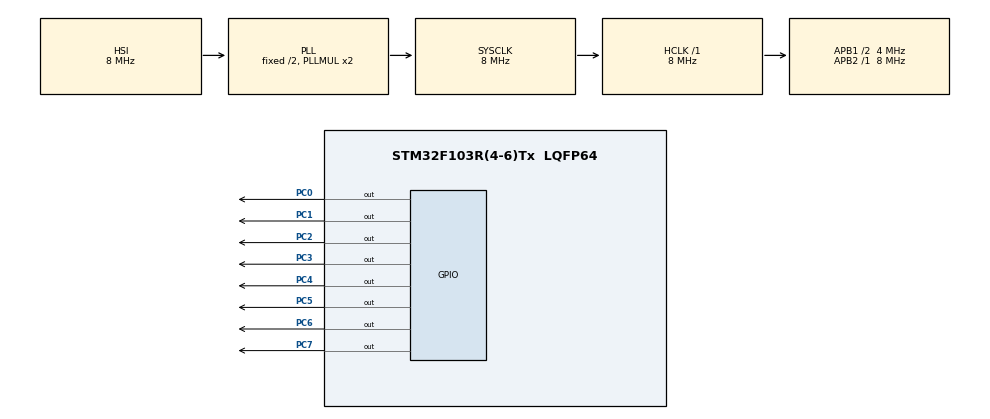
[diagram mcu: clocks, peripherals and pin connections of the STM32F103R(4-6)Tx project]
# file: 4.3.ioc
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Mcu.Family=STM32F1
Mcu.Name=STM32F103R(4-6)Tx
Mcu.Package=LQFP64
NVIC.PriorityGroup=NVIC_PRIORITYGROUP_4
NVIC.TIM3_IRQn=true\:0\:0\:false\:false\:true\:true\:true
PC0.Signal=GPIO_Output
PC1.Signal=GPIO_Output
PC2.Signal=GPIO_Output
PC3.Signal=GPIO_Output
PC4.Signal=GPIO_Output
PC5.Signal=GPIO_Output
PC6.Signal=GPIO_Output
PC7.Signal=GPIO_Output
ProjectManager.HeapSize=0x200
ProjectManager.StackSize=0x400
ProjectManager.TargetToolchain=STM32CubeIDE
RCC.AHBFreq_Value=8000000
RCC.APB1CLKDivider=RCC_HCLK_DIV2
RCC.APB1Freq_Value=4000000
RCC.APB1TimFreq_Value=8000000
RCC.APB2Freq_Value=8000000
RCC.APB2TimFreq_Value=8000000
RCC.HCLKFreq_Value=8000000
RCC.SYSCLKFreq_VALUE=8000000
RCC.SYSCLKSource=RCC_SYSCLKSOURCE_PLLCLK
RCC.USBFreq_Value=8000000
TIM3.Period=999
TIM3.Prescaler=3999
VP_SYS_VS_ND.Mode=No_Debug
VP_TIM3_VS_ClockSourceINT.Mode=Internal
board=custom

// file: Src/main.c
/* USER CODE BEGIN Header */
/**
  ******************************************************************************
  * @file           : main.c
  * @brief          : Main program body
  ******************************************************************************
  * @attention
  *
  * <h2><center>&copy; Copyright (c) 2019 STMicroelectronics.
  * All rights reserved.</center></h2>
  *
  * This software component is licensed by ST under BSD 3-Clause license,
  * the "License"; You may not use this file except in compliance with the
  * License. You may obtain a copy of the License at:
  *                        opensource.org/licenses/BSD-3-Clause
  *
  ******************************************************************************
  */
/* USER CODE END Header */

#include "main.h"

/* USER CODE BEGIN PD */
void HAL_TIM_PeriodElapsedCallback (TIM_HandleTypeDef *htim);
/* USER CODE END PD */

TIM_HandleTypeDef htim3;

void SystemClock_Config(void);
static void MX_GPIO_Init(void);
static void MX_TIM3_Init(void);

int main(void)
{

  /* MCU Configuration--------------------------------------------------------*/

  /* Reset of all peripherals, Initializes the Flash interface and the Systick. */
  HAL_Init();

  /* Configure the system clock */
  SystemClock_Config();

  /* Initialize all configured peripherals */
  MX_GPIO_Init();
  MX_TIM3_Init();
  /* USER CODE BEGIN 2 */
  LL_GPIO_WriteOutputPort(GPIOC,0xfe);
  HAL_TIM_Base_Start_IT(&htim3);
  /* USER CODE END 2 */

  /* Infinite loop */
  while (1)
  {

  }
}

void SystemClock_Config(void)
{
  RCC_OscInitTypeDef RCC_OscInitStruct = {0};
  RCC_ClkInitTypeDef RCC_ClkInitStruct = {0};

  /** Initializes the CPU, AHB and APB busses clocks
  */
  RCC_OscInitStruct.OscillatorType = RCC_OSCILLATORTYPE_HSI;
  RCC_OscInitStruct.HSIState = RCC_HSI_ON;
  RCC_OscInitStruct.HSICalibrationValue = RCC_HSICALIBRATION_DEFAULT;
  RCC_OscInitStruct.PLL.PLLState = RCC_PLL_ON;
  RCC_OscInitStruct.PLL.PLLSource = RCC_PLLSOURCE_HSI_DIV2;
  RCC_OscInitStruct.PLL.PLLMUL = RCC_PLL_MUL2;
  if (HAL_RCC_OscConfig(&RCC_OscInitStruct) != HAL_OK)
  {
    Error_Handler();
  }
  /** Initializes the CPU, AHB and APB busses clocks
  */
  RCC_ClkInitStruct.ClockType = RCC_CLOCKTYPE_HCLK|RCC_CLOCKTYPE_SYSCLK
                              |RCC_CLOCKTYPE_PCLK1|RCC_CLOCKTYPE_PCLK2;
  RCC_ClkInitStruct.SYSCLKSource = RCC_SYSCLKSOURCE_PLLCLK;
  RCC_ClkInitStruct.AHBCLKDivider = RCC_SYSCLK_DIV1;
  RCC_ClkInitStruct.APB1CLKDivider = RCC_HCLK_DIV2;
  RCC_ClkInitStruct.APB2CLKDivider = RCC_HCLK_DIV1;

  if (HAL_RCC_ClockConfig(&RCC_ClkInitStruct, FLASH_LATENCY_0) != HAL_OK)
  {
    Error_Handler();
  }
}

static void MX_TIM3_Init(void)
{

  TIM_ClockConfigTypeDef sClockSourceConfig = {0};
  TIM_MasterConfigTypeDef sMasterConfig = {0};

  htim3.Instance = TIM3;
  htim3.Init.Prescaler = 3999;
  htim3.Init.CounterMode = TIM_COUNTERMODE_UP;
  htim3.Init.Period = 999;
  htim3.Init.ClockDivision = TIM_CLOCKDIVISION_DIV1;
  htim3.Init.AutoReloadPreload = TIM_AUTORELOAD_PRELOAD_DISABLE;
  if (HAL_TIM_Base_Init(&htim3) != HAL_OK)
  {
    Error_Handler();
  }
  sClockSourceConfig.ClockSource = TIM_CLOCKSOURCE_INTERNAL;
  if (HAL_TIM_ConfigClockSource(&htim3, &sClockSourceConfig) != HAL_OK)
  {
    Error_Handler();
  }
  sMasterConfig.MasterOutputTrigger = TIM_TRGO_RESET;
  sMasterConfig.MasterSlaveMode = TIM_MASTERSLAVEMODE_DISABLE;
  if (HAL_TIMEx_MasterConfigSynchronization(&htim3, &sMasterConfig) != HAL_OK)
  {
    Error_Handler();
  }

}

static void MX_GPIO_Init(void)
{
  LL_GPIO_InitTypeDef GPIO_InitStruct = {0};

  /* GPIO Ports Clock Enable */
  LL_APB2_GRP1_EnableClock(LL_APB2_GRP1_PERIPH_GPIOC);

  /**/
  LL_GPIO_ResetOutputPin(GPIOC, LL_GPIO_PIN_0|LL_GPIO_PIN_1|LL_GPIO_PIN_2|LL_GPIO_PIN_3
                          |LL_GPIO_PIN_4|LL_GPIO_PIN_5|LL_GPIO_PIN_6|LL_GPIO_PIN_7);

  /**/
  GPIO_InitStruct.Pin = LL_GPIO_PIN_0|LL_GPIO_PIN_1|LL_GPIO_PIN_2|LL_GPIO_PIN_3
                          |LL_GPIO_PIN_4|LL_GPIO_PIN_5|LL_GPIO_PIN_6|LL_GPIO_PIN_7;
  GPIO_InitStruct.Mode = LL_GPIO_MODE_OUTPUT;
  GPIO_InitStruct.Speed = LL_GPIO_SPEED_FREQ_LOW;
  GPIO_InitStruct.OutputType = LL_GPIO_OUTPUT_PUSHPULL;
  LL_GPIO_Init(GPIOC, &GPIO_InitStruct);

}

/* USER CODE BEGIN 4 */
void HAL_TIM_PeriodElapsedCallback (TIM_HandleTypeDef *htim)
{
	static uint8_t counter=0;
	if(htim==&htim3)
	{
		counter++;
		if(counter>=8)counter=0;
		LL_GPIO_WriteOutputPort(GPIOC,(0xfe<<counter)|(0xfe>>(8-counter)));
	}
}
/* USER CODE END 4 */

void Error_Handler(void)
{
}

/************************ (C) COPYRIGHT STMicroelectronics *****END OF FILE****/
